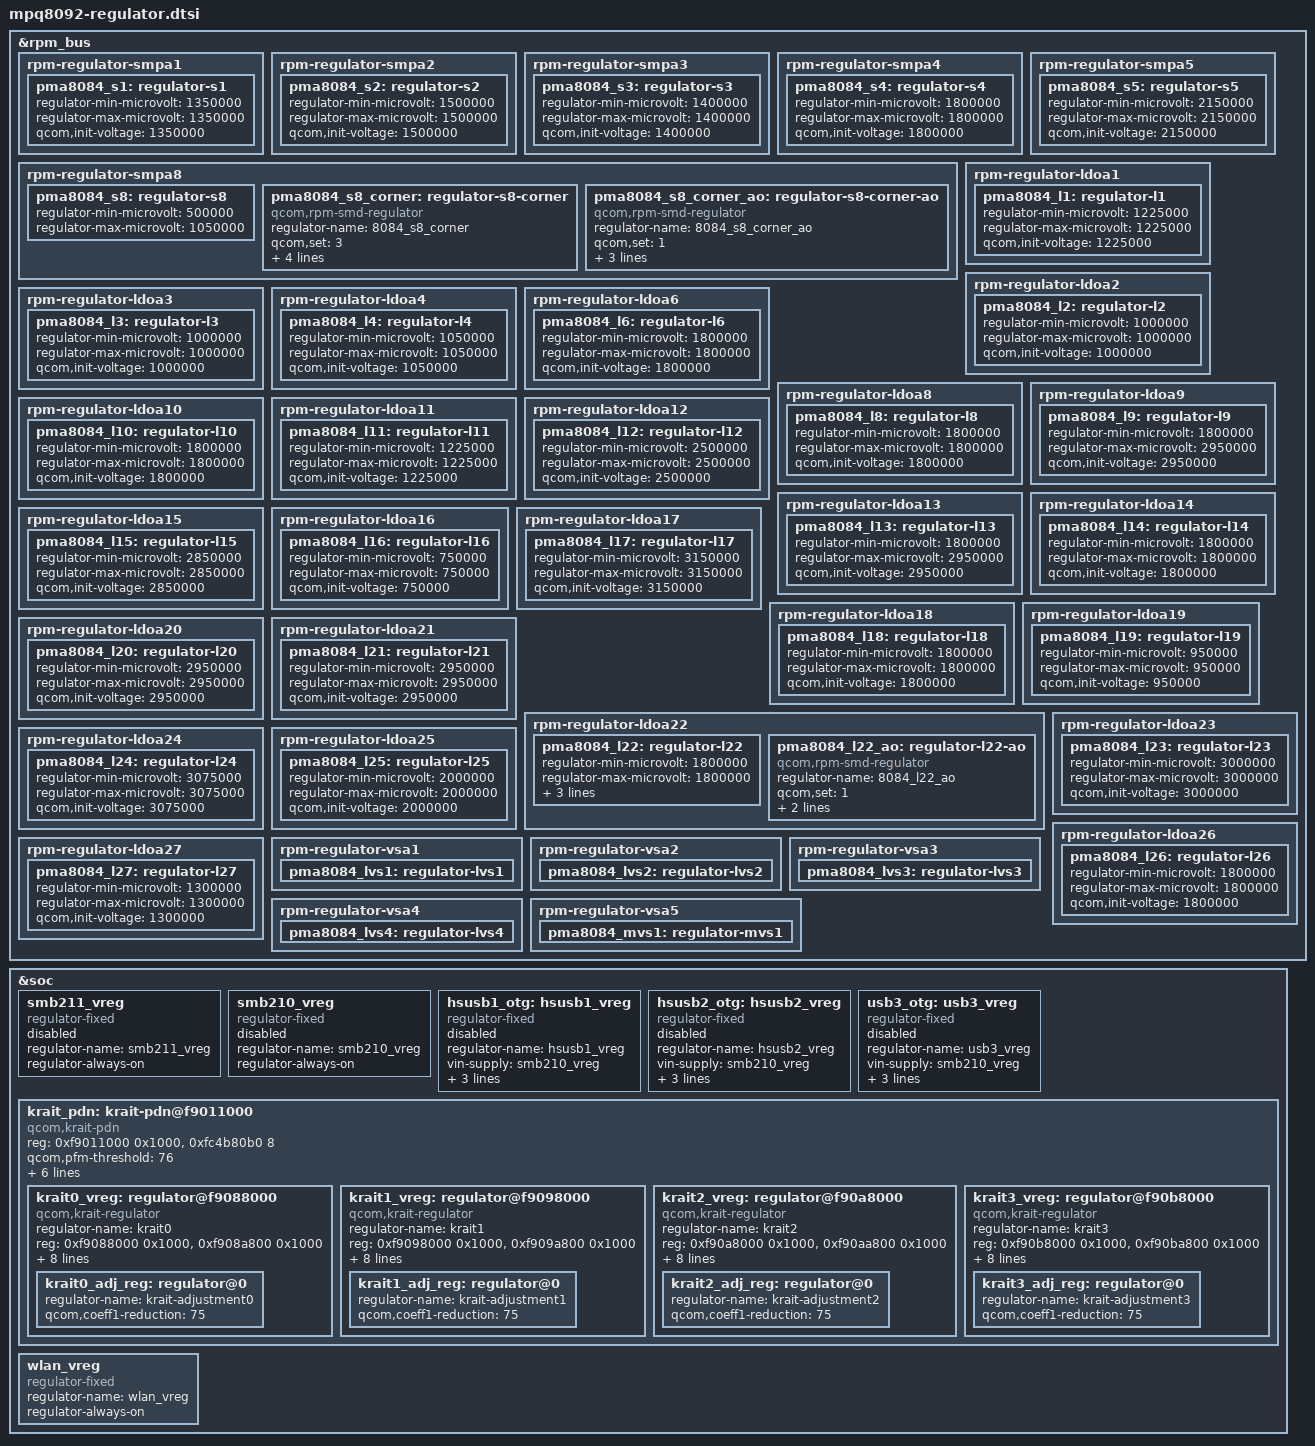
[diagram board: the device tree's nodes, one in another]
/* Copyright (c) 2012-2014, The Linux Foundation. All rights reserved.
 *
 * This program is free software; you can redistribute it and/or modify
 * it under the terms of the GNU General Public License version 2 and
 * only version 2 as published by the Free Software Foundation.
 *
 * This program is distributed in the hope that it will be useful,
 * but WITHOUT ANY WARRANTY; without even the implied warranty of
 * MERCHANTABILITY or FITNESS FOR A PARTICULAR PURPOSE.  See the
 * GNU General Public License for more details.
 */


/* RPM controlled regulators: */
&rpm_bus {
	rpm-regulator-smpa1 {
		status = "okay";
		pma8084_s1: regulator-s1 {
			regulator-min-microvolt = <1350000>;
			regulator-max-microvolt = <1350000>;
			qcom,init-voltage = <1350000>;
			status = "okay";
		};
	};

	/* PMA8084 S2 + S12 = 2 phase VDDPX_1 & PCDDR3 supply */
	rpm-regulator-smpa2 {
		status = "okay";
		pma8084_s2: regulator-s2 {
			regulator-min-microvolt = <1500000>;
			regulator-max-microvolt = <1500000>;
			qcom,init-voltage = <1500000>;
			status = "okay";
		};
	};

	rpm-regulator-smpa3 {
		status = "okay";
		pma8084_s3: regulator-s3 {
			regulator-min-microvolt = <1400000>;
			regulator-max-microvolt = <1400000>;
			qcom,init-voltage = <1400000>;
			status = "okay";
		};
	};

	rpm-regulator-smpa4 {
		status = "okay";
		pma8084_s4: regulator-s4 {
			regulator-min-microvolt = <1800000>;
			regulator-max-microvolt = <1800000>;
			qcom,init-voltage = <1800000>;
			status = "okay";
		};
	};

	rpm-regulator-smpa5 {
		status = "okay";
		pma8084_s5: regulator-s5 {
			regulator-min-microvolt = <2150000>;
			regulator-max-microvolt = <2150000>;
			qcom,init-voltage = <2150000>;
			status = "okay";
		};
	};

	/* PMA8084 S8 + S9 + S10 + S11 */
	rpm-regulator-smpa8 {
		status = "okay";
		pma8084_s8: regulator-s8 {
			regulator-min-microvolt = <500000>;
			regulator-max-microvolt = <1050000>;
			status = "okay";
		};

		pma8084_s8_corner: regulator-s8-corner {
			compatible = "qcom,rpm-smd-regulator";
			regulator-name = "8084_s8_corner";
			qcom,set = <3>;
			regulator-min-microvolt = <1>;
			regulator-max-microvolt = <7>;
			qcom,consumer-supplies = "vdd_dig", "";
			qcom,use-voltage-corner;
		};

		pma8084_s8_corner_ao: regulator-s8-corner-ao {
			compatible = "qcom,rpm-smd-regulator";
			regulator-name = "8084_s8_corner_ao";
			qcom,set = <1>;
			regulator-min-microvolt = <1>;
			regulator-max-microvolt = <7>;
			qcom,use-voltage-corner;
		};
	};

	rpm-regulator-ldoa1 {
		status = "okay";
		pma8084_l1: regulator-l1 {
			regulator-min-microvolt = <1225000>;
			regulator-max-microvolt = <1225000>;
			qcom,init-voltage = <1225000>;
			status = "okay";
		};
	};

	rpm-regulator-ldoa2 {
		status = "okay";
		pma8084_l2: regulator-l2 {
			regulator-min-microvolt = <1000000>;
			regulator-max-microvolt = <1000000>;
			qcom,init-voltage = <1000000>;
			status = "okay";
		};
	};

	rpm-regulator-ldoa3 {
		status = "okay";
		pma8084_l3: regulator-l3 {
			regulator-min-microvolt = <1000000>;
			regulator-max-microvolt = <1000000>;
			qcom,init-voltage = <1000000>;
			status = "okay";
		};
	};

	rpm-regulator-ldoa4 {
		status = "okay";
		pma8084_l4: regulator-l4 {
			regulator-min-microvolt = <1050000>;
			regulator-max-microvolt = <1050000>;
			qcom,init-voltage = <1050000>;
			status = "okay";
		};
	};

	rpm-regulator-ldoa6 {
		status = "okay";
		pma8084_l6: regulator-l6 {
			regulator-min-microvolt = <1800000>;
			regulator-max-microvolt = <1800000>;
			qcom,init-voltage = <1800000>;
			status = "okay";
		};
	};

	rpm-regulator-ldoa8 {
		status = "okay";
		pma8084_l8: regulator-l8 {
			regulator-min-microvolt = <1800000>;
			regulator-max-microvolt = <1800000>;
			qcom,init-voltage = <1800000>;
			status = "okay";
		};
	};

	rpm-regulator-ldoa9 {
		status = "okay";
		pma8084_l9: regulator-l9 {
			regulator-min-microvolt = <1800000>;
			regulator-max-microvolt = <2950000>;
			qcom,init-voltage = <2950000>;
			status = "okay";
		};
	};

	rpm-regulator-ldoa10 {
		status = "okay";
		pma8084_l10: regulator-l10 {
			regulator-min-microvolt = <1800000>;
			regulator-max-microvolt = <1800000>;
			qcom,init-voltage = <1800000>;
			status = "okay";
		};
	};

	rpm-regulator-ldoa11 {
		status = "okay";
		pma8084_l11: regulator-l11 {
			regulator-min-microvolt = <1225000>;
			regulator-max-microvolt = <1225000>;
			qcom,init-voltage = <1225000>;
			status = "okay";
		};
	};

	rpm-regulator-ldoa12 {
		status = "okay";
		pma8084_l12: regulator-l12 {
			regulator-min-microvolt = <2500000>;
			regulator-max-microvolt = <2500000>;
			qcom,init-voltage = <2500000>;
			status = "okay";
		};
	};

	rpm-regulator-ldoa13 {
		status = "okay";
		pma8084_l13: regulator-l13 {
			regulator-min-microvolt = <1800000>;
			regulator-max-microvolt = <2950000>;
			qcom,init-voltage = <2950000>;
			status = "okay";
		};
	};

	rpm-regulator-ldoa14 {
		status = "okay";
		pma8084_l14: regulator-l14 {
			regulator-min-microvolt = <1800000>;
			regulator-max-microvolt = <1800000>;
			qcom,init-voltage = <1800000>;
			status = "okay";
		};
	};

	rpm-regulator-ldoa15 {
		status = "okay";
		pma8084_l15: regulator-l15 {
			regulator-min-microvolt = <2850000>;
			regulator-max-microvolt = <2850000>;
			qcom,init-voltage = <2850000>;
			status = "okay";
		};
	};

	rpm-regulator-ldoa16 {
		status = "okay";
		pma8084_l16: regulator-l16 {
			regulator-min-microvolt = <750000>;
			regulator-max-microvolt = <750000>;
			qcom,init-voltage = <750000>;
			status = "okay";
		};
	};

	rpm-regulator-ldoa17 {
		status = "okay";
		pma8084_l17: regulator-l17 {
			regulator-min-microvolt = <3150000>;
			regulator-max-microvolt = <3150000>;
			qcom,init-voltage = <3150000>;
			status = "okay";
		};
	};

	rpm-regulator-ldoa18 {
		status = "okay";
		pma8084_l18: regulator-l18 {
			regulator-min-microvolt = <1800000>;
			regulator-max-microvolt = <1800000>;
			qcom,init-voltage = <1800000>;
			status = "okay";
		};
	};

	rpm-regulator-ldoa19 {
		status = "okay";
		pma8084_l19: regulator-l19 {
			regulator-min-microvolt = <950000>;
			regulator-max-microvolt = <950000>;
			qcom,init-voltage = <950000>;
			status = "okay";
		};
	};

	rpm-regulator-ldoa20 {
		status = "okay";
		pma8084_l20: regulator-l20 {
			regulator-min-microvolt = <2950000>;
			regulator-max-microvolt = <2950000>;
			qcom,init-voltage = <2950000>;
			status = "okay";
		};
	};

	rpm-regulator-ldoa21 {
		status = "okay";
		pma8084_l21: regulator-l21 {
			regulator-min-microvolt = <2950000>;
			regulator-max-microvolt = <2950000>;
			qcom,init-voltage = <2950000>;
			status = "okay";
		};
	};

	rpm-regulator-ldoa22 {
		status = "okay";
		pma8084_l22: regulator-l22 {
			regulator-min-microvolt = <1800000>;
			regulator-max-microvolt = <1800000>;
			qcom,init-voltage = <1800000>;
			proxy-supply = <&pma8084_l22>;
			qcom,proxy-consumer-enable;
			status = "okay";
		};

		pma8084_l22_ao: regulator-l22-ao {
			compatible = "qcom,rpm-smd-regulator";
			regulator-name = "8084_l22_ao";
			qcom,set = <1>;
			regulator-min-microvolt = <1800000>;
			regulator-max-microvolt = <1800000>;
		};
	};

	rpm-regulator-ldoa23 {
		status = "okay";
		pma8084_l23: regulator-l23 {
			regulator-min-microvolt = <3000000>;
			regulator-max-microvolt = <3000000>;
			qcom,init-voltage = <3000000>;
			status = "okay";
		};
	};

	rpm-regulator-ldoa24 {
		status = "okay";
		pma8084_l24: regulator-l24 {
			regulator-min-microvolt = <3075000>;
			regulator-max-microvolt = <3075000>;
			qcom,init-voltage = <3075000>;
			status = "okay";
		};
	};

	rpm-regulator-ldoa25 {
		status = "okay";
		pma8084_l25: regulator-l25 {
			regulator-min-microvolt = <2000000>;
			regulator-max-microvolt = <2000000>;
			qcom,init-voltage = <2000000>;
			status = "okay";
		};
	};

	rpm-regulator-ldoa26 {
		status = "okay";
		pma8084_l26: regulator-l26 {
			regulator-min-microvolt = <1800000>;
			regulator-max-microvolt = <1800000>;
			qcom,init-voltage = <1800000>;
			status = "okay";
		};
	};

	rpm-regulator-ldoa27 {
		status = "okay";
		pma8084_l27: regulator-l27 {
			regulator-min-microvolt = <1300000>;
			regulator-max-microvolt = <1300000>;
			qcom,init-voltage = <1300000>;
			status = "okay";
		};
	};

	rpm-regulator-vsa1 {
		status = "okay";
		pma8084_lvs1: regulator-lvs1 {
			status = "okay";
		};
	};

	rpm-regulator-vsa2 {
		status = "okay";
		pma8084_lvs2: regulator-lvs2 {
			status = "okay";
		};
	};

	rpm-regulator-vsa3 {
		status = "okay";
		pma8084_lvs3: regulator-lvs3 {
			status = "okay";
		};
	};

	rpm-regulator-vsa4 {
		status = "okay";
		pma8084_lvs4: regulator-lvs4 {
			status = "okay";
		};
	};

	rpm-regulator-vsa5 {
		status = "okay";
		pma8084_mvs1: regulator-mvs1 {
			status = "okay";
		};
	};
};

&soc {
	smb211_vreg: smb211_vreg {
		compatible = "regulator-fixed";
		regulator-name = "smb211_vreg";
		regulator-always-on;
		status = "disabled";
	};

	smb210_vreg: smb210_vreg {
		compatible = "regulator-fixed";
		regulator-name = "smb210_vreg";
		regulator-always-on;
		status = "disabled";
	};

	hsusb1_otg: hsusb1_vreg {
		compatible = "regulator-fixed";
		regulator-name = "hsusb1_vreg";
		vin-supply = <&smb210_vreg>;
		startup-delay-us = <16000>;
		gpio = <&pma8084_gpios 9 0>;
		enable-active-high;
		status = "disabled";
	};

	hsusb2_otg: hsusb2_vreg {
		compatible = "regulator-fixed";
		regulator-name = "hsusb2_vreg";
		vin-supply = <&smb210_vreg>;
		startup-delay-us = <16000>;
		gpio = <&pma8084_gpios 10 0>;
		enable-active-high;
		status = "disabled";
	};

	usb3_otg: usb3_vreg {
		compatible = "regulator-fixed";
		regulator-name = "usb3_vreg";
		vin-supply = <&smb210_vreg>;
		startup-delay-us = <16000>;
		gpio = <&pma8084_gpios 8 0>;
		enable-active-high;
		status = "disabled";
	};

	krait_pdn: krait-pdn@f9011000 {
		reg = <0xf9011000 0x1000>,
		      <0xfc4b80b0 8>;
		reg-names = "apcs_gcc", "phase-scaling-efuse";
		compatible = "qcom,krait-pdn";
		#address-cells = <1>;
		#size-cells = <1>;
		ranges;
		qcom,pfm-threshold = <76>;
		qcom,use-phase-switching;
		qcom,cores-per-phase = <2>;
		qcom,valid-phases = <1 2>;
		qcom,phase-coeff-threshold = <2000000 4000000>;
		qcom,phase-scaling-factor-bits-pos = <14>;
		qcom,valid-scaling-factor-versions = <1 0 0 0>;

		krait0_vreg: regulator@f9088000 {
			compatible = "qcom,krait-regulator";
			regulator-name = "krait0";
			reg = <0xf9088000 0x1000>, /* APCS_ALIAS0_KPSS_ACS */
				<0xf908a800 0x1000>; /* APCS_ALIAS0_KPSS_MDD */
			reg-names = "acs", "mdd";
			regulator-min-microvolt = <500000>;
			regulator-max-microvolt = <1100000>;
			qcom,headroom-voltage = <150000>;
			qcom,retention-voltage = <675000>;
			qcom,ldo-default-voltage = <750000>;
			qcom,ldo-threshold-voltage = <850000>;
			qcom,ldo-delta-voltage = <12500>;
			qcom,cpu-num = <0>;
			krait0_adj_reg: regulator@0 {
				regulator-name = "krait-adjustment0";
				qcom,coeff1-reduction = <75>;
			};
		};

		krait1_vreg: regulator@f9098000 {
			compatible = "qcom,krait-regulator";
			regulator-name = "krait1";
			reg = <0xf9098000 0x1000>, /* APCS_ALIAS1_KPSS_ACS */
				<0xf909a800 0x1000>; /* APCS_ALIAS1_KPSS_MDD */
			reg-names = "acs", "mdd";
			regulator-min-microvolt = <500000>;
			regulator-max-microvolt = <1100000>;
			qcom,headroom-voltage = <150000>;
			qcom,retention-voltage = <675000>;
			qcom,ldo-default-voltage = <750000>;
			qcom,ldo-threshold-voltage = <850000>;
			qcom,ldo-delta-voltage = <12500>;
			qcom,cpu-num = <1>;
			krait1_adj_reg: regulator@0 {
				regulator-name = "krait-adjustment1";
				qcom,coeff1-reduction = <75>;
			};
		};

		krait2_vreg: regulator@f90a8000 {
			compatible = "qcom,krait-regulator";
			regulator-name = "krait2";
			reg = <0xf90a8000 0x1000>, /* APCS_ALIAS2_KPSS_ACS */
				<0xf90aa800 0x1000>; /* APCS_ALIAS2_KPSS_MDD */
			reg-names = "acs", "mdd";
			regulator-min-microvolt = <500000>;
			regulator-max-microvolt = <1100000>;
			qcom,headroom-voltage = <150000>;
			qcom,retention-voltage = <675000>;
			qcom,ldo-default-voltage = <750000>;
			qcom,ldo-threshold-voltage = <850000>;
			qcom,ldo-delta-voltage = <12500>;
			qcom,cpu-num = <2>;
			krait2_adj_reg: regulator@0 {
				regulator-name = "krait-adjustment2";
				qcom,coeff1-reduction = <75>;
			};
		};

		krait3_vreg: regulator@f90b8000 {
			compatible = "qcom,krait-regulator";
			regulator-name = "krait3";
			reg = <0xf90b8000 0x1000>, /* APCS_ALIAS3_KPSS_ACS */
				<0xf90ba800 0x1000>; /* APCS_ALIAS3_KPSS_MDD */
			reg-names = "acs", "mdd";
			regulator-min-microvolt = <500000>;
			regulator-max-microvolt = <1100000>;
			qcom,headroom-voltage = <150000>;
			qcom,retention-voltage = <675000>;
			qcom,ldo-default-voltage = <750000>;
			qcom,ldo-threshold-voltage = <850000>;
			qcom,ldo-delta-voltage = <12500>;
			qcom,cpu-num = <3>;
			krait3_adj_reg: regulator@0 {
				regulator-name = "krait-adjustment3";
				qcom,coeff1-reduction = <75>;
			};
		};
	};

	wlan_vreg: wlan_vreg {
		compatible = "regulator-fixed";
		regulator-name = "wlan_vreg";
		regulator-always-on;
		status = "ok";
	};
};
